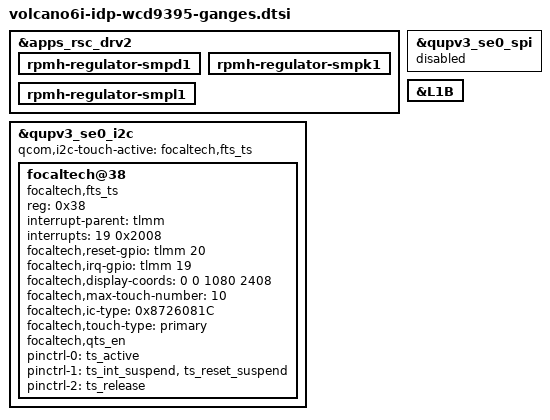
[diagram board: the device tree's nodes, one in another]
#include "volcano-idp-wcd9395.dtsi"

&apps_rsc_drv2 {
	rpmh-regulator-smpd1 {
		status = "ok";
	};

	rpmh-regulator-smpk1 {
		status = "ok";
	};

	rpmh-regulator-smpl1 {
		status = "ok";
	};
};

&qupv3_se0_spi {
	status = "disabled";
};

&qupv3_se0_i2c {
	#address-cells = <1>;
	#size-cells = <0>;

	status = "ok";
	qcom,i2c-touch-active = "focaltech,fts_ts";

	focaltech@38 {
		compatible = "focaltech,fts_ts";
		reg = <0x38>;

		interrupt-parent = <&tlmm>;
		interrupts = <19 0x2008>;
		focaltech,reset-gpio = <&tlmm 20 0x00>;
		focaltech,irq-gpio = <&tlmm 19 0x2008>;
		focaltech,display-coords = <0 0 1080 2408>;
		focaltech,max-touch-number = <10>;
		focaltech,ic-type = <0x8726081C>;
		focaltech,touch-type = "primary";
		focaltech,qts_en;

		pinctrl-names = "pmx_ts_active","pmx_ts_suspend","pmx_ts_release";
		pinctrl-0 = <&ts_active>;
		pinctrl-1 = <&ts_int_suspend &ts_reset_suspend>;
		pinctrl-2 = <&ts_release>;
	};
};

&L1B {
	status = "ok";
};
